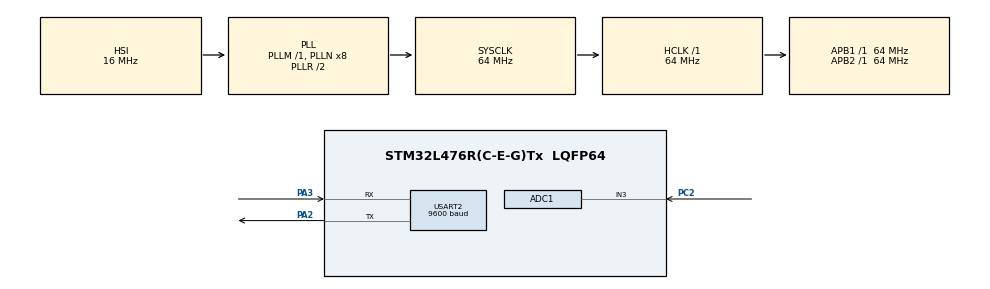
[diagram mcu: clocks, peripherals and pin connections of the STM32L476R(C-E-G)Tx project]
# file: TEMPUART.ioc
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ADC1.Channel-0\#ChannelRegularConversion=ADC_CHANNEL_3
ADC1.ContinuousConvMode=ENABLE
ADC1.NbrOfConversionFlag=1
ADC1.OffsetNumber-0\#ChannelRegularConversion=ADC_OFFSET_NONE
ADC1.Overrun=ADC_OVR_DATA_OVERWRITTEN
ADC1.Rank-0\#ChannelRegularConversion=1
ADC1.SamplingTime-0\#ChannelRegularConversion=ADC_SAMPLETIME_2CYCLES_5
ADC1.master=1
Mcu.Family=STM32L4
Mcu.Name=STM32L476R(C-E-G)Tx
Mcu.Package=LQFP64
NVIC.PriorityGroup=NVIC_PRIORITYGROUP_4
PA2.Mode=Asynchronous
PA2.Signal=USART2_TX
PA3.Mode=Asynchronous
PA3.Signal=USART2_RX
PC2.Signal=ADCx_IN3
PH0-OSC_IN\ (PH0).Mode=HSE-External-Oscillator
PH0-OSC_IN\ (PH0).Signal=RCC_OSC_IN
PH1-OSC_OUT\ (PH1).Mode=HSE-External-Oscillator
PH1-OSC_OUT\ (PH1).Signal=RCC_OSC_OUT
ProjectManager.HeapSize=0x200
ProjectManager.StackSize=0x400
ProjectManager.TargetToolchain=STM32CubeIDE
RCC.ADCFreq_Value=64000000
RCC.AHBFreq_Value=64000000
RCC.APB1Freq_Value=64000000
RCC.APB1TimFreq_Value=64000000
RCC.APB2Freq_Value=64000000
RCC.APB2TimFreq_Value=64000000
RCC.CortexFreq_Value=64000000
RCC.HCLKFreq_Value=64000000
RCC.HSE_VALUE=8000000
RCC.HSI_VALUE=16000000
RCC.LSE_VALUE=32768
RCC.MSI_VALUE=4000000
RCC.PLLSourceVirtual=RCC_PLLSOURCE_HSI
RCC.SYSCLKFreq_VALUE=64000000
RCC.SYSCLKSource=RCC_SYSCLKSOURCE_PLLCLK
RCC.USBFreq_Value=64000000
RCC.VCOOutputFreq_Value=128000000
SH.ADCx_IN3.0=ADC1_IN3,IN3-Single-Ended
USART2.BaudRate=9600
USART2.VirtualMode-Asynchronous=VM_ASYNC
board=custom

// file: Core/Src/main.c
/* USER CODE BEGIN Header */
/**
  ******************************************************************************
  * @file           : main.c
  * @brief          : Main program body
  ******************************************************************************
  * @attention
  *
  * Copyright (c) 2024 STMicroelectronics.
  * All rights reserved.
  *
  * This software is licensed under terms that can be found in the LICENSE file
  * in the root directory of this software component.
  * If no LICENSE file comes with this software, it is provided AS-IS.
  *
  ******************************************************************************
  */
/* USER CODE END Header */
#include "main.h"

ADC_HandleTypeDef hadc1;

UART_HandleTypeDef huart2;

void SystemClock_Config(void);
static void MX_GPIO_Init(void);
static void MX_ADC1_Init(void);
static void MX_USART2_UART_Init(void);
/* USER CODE BEGIN PFP */
void uart_sText(UART_HandleTypeDef * huart, char buffer[], int m)
{

	HAL_UART_Transmit(huart,(uint8_t *)buffer, strlen(buffer) , HAL_MAX_DELAY);
	if(m==1)HAL_UART_Transmit(huart, "\r\n", 2, HAL_MAX_DELAY);

}
void uart_sFloat(UART_HandleTypeDef * huart, float p, int m)
{

	char buffer[10];
	sprintf(buffer, "%5.2f",p);
	HAL_UART_Transmit(huart, (uint8_t *)buffer, strlen(buffer), HAL_MAX_DELAY);
	if(m==1)HAL_UART_Transmit(huart, "\r\n", 2, HAL_MAX_DELAY);

}
/* USER CODE END PFP */

int main(void)
{
  /* USER CODE BEGIN 1 */
uint32_t adcResult;
float Temperature;
  /* USER CODE END 1 */

  /* MCU Configuration--------------------------------------------------------*/

  /* Reset of all peripherals, Initializes the Flash interface and the Systick. */
  HAL_Init();

  /* Configure the system clock */
  SystemClock_Config();

  /* Initialize all configured peripherals */
  MX_GPIO_Init();
  MX_ADC1_Init();
  MX_USART2_UART_Init();
  /* USER CODE BEGIN 2 */
HAL_ADC_Start(&hadc1);
  /* USER CODE END 2 */

  /* Infinite loop */
  /* USER CODE BEGIN WHILE */
  while (1)
  {

	  HAL_ADC_PollForConversion(&hadc1, 100);
	  adcResult= HAL_ADC_GetValue(&hadc1);
	  Temperature=((float)adcResult)*3300.0/4095.0;
	  uart_sText(&huart2, "mVolts = ", 0);
	  uart_sFloat(&huart2, Temperature, 1);
	  Temperature=Temperature/10;
	  uart_sText(&huart2, "Temperature = ", 0);
	  uart_sFloat(&huart2, Temperature, 1);
	  HAL_Delay(1000);

    /* USER CODE END WHILE */

  }
}

void SystemClock_Config(void)
{
  RCC_OscInitTypeDef RCC_OscInitStruct = {0};
  RCC_ClkInitTypeDef RCC_ClkInitStruct = {0};

  /** Configure the main internal regulator output voltage
  */
  if (HAL_PWREx_ControlVoltageScaling(PWR_REGULATOR_VOLTAGE_SCALE1) != HAL_OK)
  {
    Error_Handler();
  }

  /** Initializes the RCC Oscillators according to the specified parameters
  * in the RCC_OscInitTypeDef structure.
  */
  RCC_OscInitStruct.OscillatorType = RCC_OSCILLATORTYPE_HSI;
  RCC_OscInitStruct.HSIState = RCC_HSI_ON;
  RCC_OscInitStruct.HSICalibrationValue = RCC_HSICALIBRATION_DEFAULT;
  RCC_OscInitStruct.PLL.PLLState = RCC_PLL_ON;
  RCC_OscInitStruct.PLL.PLLSource = RCC_PLLSOURCE_HSI;
  RCC_OscInitStruct.PLL.PLLM = 1;
  RCC_OscInitStruct.PLL.PLLN = 8;
  RCC_OscInitStruct.PLL.PLLP = RCC_PLLP_DIV7;
  RCC_OscInitStruct.PLL.PLLQ = RCC_PLLQ_DIV2;
  RCC_OscInitStruct.PLL.PLLR = RCC_PLLR_DIV2;
  if (HAL_RCC_OscConfig(&RCC_OscInitStruct) != HAL_OK)
  {
    Error_Handler();
  }

  /** Initializes the CPU, AHB and APB buses clocks
  */
  RCC_ClkInitStruct.ClockType = RCC_CLOCKTYPE_HCLK|RCC_CLOCKTYPE_SYSCLK
                              |RCC_CLOCKTYPE_PCLK1|RCC_CLOCKTYPE_PCLK2;
  RCC_ClkInitStruct.SYSCLKSource = RCC_SYSCLKSOURCE_PLLCLK;
  RCC_ClkInitStruct.AHBCLKDivider = RCC_SYSCLK_DIV1;
  RCC_ClkInitStruct.APB1CLKDivider = RCC_HCLK_DIV1;
  RCC_ClkInitStruct.APB2CLKDivider = RCC_HCLK_DIV1;

  if (HAL_RCC_ClockConfig(&RCC_ClkInitStruct, FLASH_LATENCY_3) != HAL_OK)
  {
    Error_Handler();
  }
}

static void MX_ADC1_Init(void)
{

  ADC_MultiModeTypeDef multimode = {0};
  ADC_ChannelConfTypeDef sConfig = {0};

  /** Common config
  */
  hadc1.Instance = ADC1;
  hadc1.Init.ClockPrescaler = ADC_CLOCK_ASYNC_DIV1;
  hadc1.Init.Resolution = ADC_RESOLUTION_12B;
  hadc1.Init.DataAlign = ADC_DATAALIGN_RIGHT;
  hadc1.Init.ScanConvMode = ADC_SCAN_DISABLE;
  hadc1.Init.EOCSelection = ADC_EOC_SINGLE_CONV;
  hadc1.Init.LowPowerAutoWait = DISABLE;
  hadc1.Init.ContinuousConvMode = ENABLE;
  hadc1.Init.NbrOfConversion = 1;
  hadc1.Init.DiscontinuousConvMode = DISABLE;
  hadc1.Init.ExternalTrigConv = ADC_SOFTWARE_START;
  hadc1.Init.ExternalTrigConvEdge = ADC_EXTERNALTRIGCONVEDGE_NONE;
  hadc1.Init.DMAContinuousRequests = DISABLE;
  hadc1.Init.Overrun = ADC_OVR_DATA_OVERWRITTEN;
  hadc1.Init.OversamplingMode = DISABLE;
  if (HAL_ADC_Init(&hadc1) != HAL_OK)
  {
    Error_Handler();
  }

  /** Configure the ADC multi-mode
  */
  multimode.Mode = ADC_MODE_INDEPENDENT;
  if (HAL_ADCEx_MultiModeConfigChannel(&hadc1, &multimode) != HAL_OK)
  {
    Error_Handler();
  }

  /** Configure Regular Channel
  */
  sConfig.Channel = ADC_CHANNEL_3;
  sConfig.Rank = ADC_REGULAR_RANK_1;
  sConfig.SamplingTime = ADC_SAMPLETIME_2CYCLES_5;
  sConfig.SingleDiff = ADC_SINGLE_ENDED;
  sConfig.OffsetNumber = ADC_OFFSET_NONE;
  sConfig.Offset = 0;
  if (HAL_ADC_ConfigChannel(&hadc1, &sConfig) != HAL_OK)
  {
    Error_Handler();
  }

}

static void MX_USART2_UART_Init(void)
{

  huart2.Instance = USART2;
  huart2.Init.BaudRate = 9600;
  huart2.Init.WordLength = UART_WORDLENGTH_8B;
  huart2.Init.StopBits = UART_STOPBITS_1;
  huart2.Init.Parity = UART_PARITY_NONE;
  huart2.Init.Mode = UART_MODE_TX_RX;
  huart2.Init.HwFlowCtl = UART_HWCONTROL_NONE;
  huart2.Init.OverSampling = UART_OVERSAMPLING_16;
  huart2.Init.OneBitSampling = UART_ONE_BIT_SAMPLE_DISABLE;
  huart2.AdvancedInit.AdvFeatureInit = UART_ADVFEATURE_NO_INIT;
  if (HAL_UART_Init(&huart2) != HAL_OK)
  {
    Error_Handler();
  }

}

static void MX_GPIO_Init(void)
{

  /* GPIO Ports Clock Enable */
  __HAL_RCC_GPIOH_CLK_ENABLE();
  __HAL_RCC_GPIOC_CLK_ENABLE();
  __HAL_RCC_GPIOA_CLK_ENABLE();

}

void Error_Handler(void)
{
  __disable_irq();
  while (1)
  {
  }
}
